AUTOSAR XML (schema 4-0-3)
standard types defined: Boolean, UInt16, UInt8
package /AUTOSAR_Platform/DataConstrs
  range DC_Boolean: raw 0..1
  range DC_UInt16: raw 0..65535
  range DC_UInt8: raw 0..255
package /PATAC/MSM/ComponentTypes
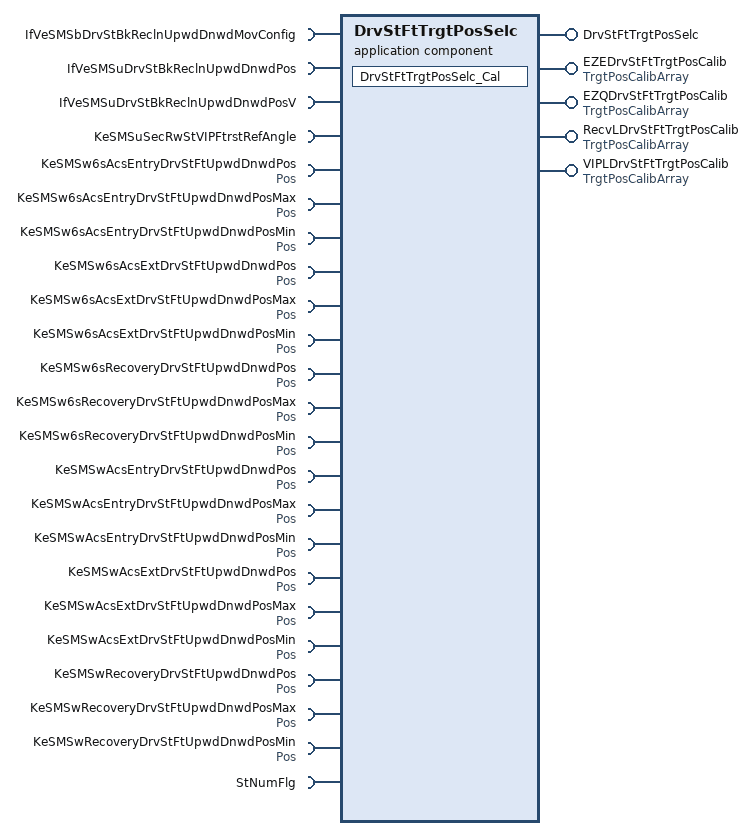
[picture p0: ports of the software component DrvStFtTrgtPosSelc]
  application sw component type DrvStFtTrgtPosSelc
    5 x provide port:
      DrvStFtTrgtPosSelc: server-com-spec{operation=Cal, queue-length=1}, provided-interface=DrvStFtTrgtPosSelc
      EZEDrvStFtTrgtPosCalib: nonqueued-sender-com-spec{data-element=TrgtPosArray, init-value=[4095, 4095, 4095]}, provided-interface=TrgtPosCalibArray
      EZQDrvStFtTrgtPosCalib: nonqueued-sender-com-spec{data-element=TrgtPosArray, init-value=[4095, 4095, 4095]}, provided-interface=TrgtPosCalibArray
      RecvLDrvStFtTrgtPosCalib: nonqueued-sender-com-spec{data-element=TrgtPosArray, init-value=[4095, 4095, 4095]}, provided-interface=TrgtPosCalibArray
      VIPLDrvStFtTrgtPosCalib: nonqueued-sender-com-spec{data-element=TrgtPosArray, init-value=[4095, 4095, 4095]}, provided-interface=TrgtPosCalibArray
    23 x require port:
      IfVeSMSbDrvStBkReclnUpwdDnwdMovConfig: nonqueued-receiver-com-spec{data-element=IfVeSMSbDrvStBkReclnUpwdDnwdMovConfig/Val, filter=data-filter-type=ALWAYS, init-value=0}, required-interface=IfVeSMSbDrvStBkReclnUpwdDnwdMovConfig
      IfVeSMSuDrvStBkReclnUpwdDnwdPos: nonqueued-receiver-com-spec{data-element=IfVeSMSuDrvStBkReclnUpwdDnwdPos/Val, filter=data-filter-type=ALWAYS, init-value=0}, required-interface=IfVeSMSuDrvStBkReclnUpwdDnwdPos
      IfVeSMSuDrvStBkReclnUpwdDnwdPosV: nonqueued-receiver-com-spec{data-element=IfVeSMSuDrvStBkReclnUpwdDnwdPosV/Val, filter=data-filter-type=ALWAYS, init-value=0}, required-interface=IfVeSMSuDrvStBkReclnUpwdDnwdPosV
      KeSMSuSecRwStVIPFtrstRefAngle: parameter-require-com-spec{init-value=110, parameter=KeSMSuSecRwStVIPFtrstRefAngle/Val}, required-interface=KeSMSuSecRwStVIPFtrstRefAngle
      KeSMSw6sAcsEntryDrvStFtUpwdDnwdPos: parameter-require-com-spec{init-value=0, parameter=Pos/Val}, required-interface=Pos
      KeSMSw6sAcsEntryDrvStFtUpwdDnwdPosMax: parameter-require-com-spec{init-value=0, parameter=Pos/Val}, required-interface=Pos
      KeSMSw6sAcsEntryDrvStFtUpwdDnwdPosMin: parameter-require-com-spec{init-value=0, parameter=Pos/Val}, required-interface=Pos
      KeSMSw6sAcsExtDrvStFtUpwdDnwdPos: parameter-require-com-spec{init-value=0, parameter=Pos/Val}, required-interface=Pos
      KeSMSw6sAcsExtDrvStFtUpwdDnwdPosMax: parameter-require-com-spec{init-value=0, parameter=Pos/Val}, required-interface=Pos
      KeSMSw6sAcsExtDrvStFtUpwdDnwdPosMin: parameter-require-com-spec{init-value=0, parameter=Pos/Val}, required-interface=Pos
      KeSMSw6sRecoveryDrvStFtUpwdDnwdPos: parameter-require-com-spec{init-value=0, parameter=Pos/Val}, required-interface=Pos
      KeSMSw6sRecoveryDrvStFtUpwdDnwdPosMax: parameter-require-com-spec{init-value=0, parameter=Pos/Val}, required-interface=Pos
      KeSMSw6sRecoveryDrvStFtUpwdDnwdPosMin: parameter-require-com-spec{init-value=0, parameter=Pos/Val}, required-interface=Pos
      KeSMSwAcsEntryDrvStFtUpwdDnwdPos: parameter-require-com-spec{init-value=0, parameter=Pos/Val}, required-interface=Pos
      KeSMSwAcsEntryDrvStFtUpwdDnwdPosMax: parameter-require-com-spec{init-value=0, parameter=Pos/Val}, required-interface=Pos
      KeSMSwAcsEntryDrvStFtUpwdDnwdPosMin: parameter-require-com-spec{init-value=0, parameter=Pos/Val}, required-interface=Pos
      KeSMSwAcsExtDrvStFtUpwdDnwdPos: parameter-require-com-spec{init-value=0, parameter=Pos/Val}, required-interface=Pos
      KeSMSwAcsExtDrvStFtUpwdDnwdPosMax: parameter-require-com-spec{init-value=0, parameter=Pos/Val}, required-interface=Pos
      KeSMSwAcsExtDrvStFtUpwdDnwdPosMin: parameter-require-com-spec{init-value=0, parameter=Pos/Val}, required-interface=Pos
      KeSMSwRecoveryDrvStFtUpwdDnwdPos: parameter-require-com-spec{init-value=0, parameter=Pos/Val}, required-interface=Pos
      KeSMSwRecoveryDrvStFtUpwdDnwdPosMax: parameter-require-com-spec{init-value=0, parameter=Pos/Val}, required-interface=Pos
      KeSMSwRecoveryDrvStFtUpwdDnwdPosMin: parameter-require-com-spec{init-value=0, parameter=Pos/Val}, required-interface=Pos
      StNumFlg: required-interface=StNumFlg
        required-com-specs:
          data-element=Is4s, filter=data-filter-type=ALWAYS, init-value=0
          data-element=Is6s, filter=data-filter-type=ALWAYS, init-value=0
          data-element=Is6s7s, filter=data-filter-type=ALWAYS, init-value=0
          data-element=Is7s, filter=data-filter-type=ALWAYS, init-value=0
    behavior DrvStFtTrgtPosSelc_InternalBehavior
      operation invoked event OIT_DrvStFtTrgtPosSelc_Cal_DrvStFtTrgtPosSelc_Cal: start-on-event=DrvStFtTrgtPosSelc_Cal, operation=DrvStFtTrgtPosSelc.Cal
      runnable DrvStFtTrgtPosSelc_Cal
        data-receive-point-by-arguments:
          7 x access:
            REC_IfVeSMSbDrvStBkReclnUpwdDnwdMovConfig_Val: accessed-variable=IfVeSMSbDrvStBkReclnUpwdDnwdMovConfig.Val
            REC_IfVeSMSuDrvStBkReclnUpwdDnwdPos_Val: accessed-variable=IfVeSMSuDrvStBkReclnUpwdDnwdPos.Val
            REC_IfVeSMSuDrvStBkReclnUpwdDnwdPosV_Val: accessed-variable=IfVeSMSuDrvStBkReclnUpwdDnwdPosV.Val
            REC_StNumFlg_Is4s: accessed-variable=StNumFlg.Is4s
            REC_StNumFlg_Is6s: accessed-variable=StNumFlg.Is6s
            REC_StNumFlg_Is6s7s: accessed-variable=StNumFlg.Is6s7s
            REC_StNumFlg_Is7s: accessed-variable=StNumFlg.Is7s
        data-send-points:
          4 x access:
            SEND_EZEDrvStFtTrgtPosCalib_TrgtPosArray: accessed-variable=EZEDrvStFtTrgtPosCalib.TrgtPosArray
            SEND_EZQDrvStFtTrgtPosCalib_TrgtPosArray: accessed-variable=EZQDrvStFtTrgtPosCalib.TrgtPosArray
            SEND_RecvLDrvStFtTrgtPosCalib_TrgtPosArray: accessed-variable=RecvLDrvStFtTrgtPosCalib.TrgtPosArray
            SEND_VIPLDrvStFtTrgtPosCalib_TrgtPosArray: accessed-variable=VIPLDrvStFtTrgtPosCalib.TrgtPosArray
        19 x parameter access:
          PA_KeSMSuSecRwStVIPFtrstRefAngle_Val: accessed-parameter=KeSMSuSecRwStVIPFtrstRefAngle.Val
          PA_KeSMSw6sAcsEntryDrvStFtUpwdDnwdPos_Val: accessed-parameter=KeSMSw6sAcsEntryDrvStFtUpwdDnwdPos.Val
          PA_KeSMSw6sAcsEntryDrvStFtUpwdDnwdPosMax_Val: accessed-parameter=KeSMSw6sAcsEntryDrvStFtUpwdDnwdPosMax.Val
          PA_KeSMSw6sAcsEntryDrvStFtUpwdDnwdPosMin_Val: accessed-parameter=KeSMSw6sAcsEntryDrvStFtUpwdDnwdPosMin.Val
          PA_KeSMSw6sAcsExtDrvStFtUpwdDnwdPos_Val: accessed-parameter=KeSMSw6sAcsExtDrvStFtUpwdDnwdPos.Val
          PA_KeSMSw6sAcsExtDrvStFtUpwdDnwdPosMax_Val: accessed-parameter=KeSMSw6sAcsExtDrvStFtUpwdDnwdPosMax.Val
          PA_KeSMSw6sAcsExtDrvStFtUpwdDnwdPosMin_Val: accessed-parameter=KeSMSw6sAcsExtDrvStFtUpwdDnwdPosMin.Val
          PA_KeSMSw6sRecoveryDrvStFtUpwdDnwdPos_Val: accessed-parameter=KeSMSw6sRecoveryDrvStFtUpwdDnwdPos.Val
          PA_KeSMSw6sRecoveryDrvStFtUpwdDnwdPosMax_Val: accessed-parameter=KeSMSw6sRecoveryDrvStFtUpwdDnwdPosMax.Val
          PA_KeSMSw6sRecoveryDrvStFtUpwdDnwdPosMin_Val: accessed-parameter=KeSMSw6sRecoveryDrvStFtUpwdDnwdPosMin.Val
          PA_KeSMSwAcsEntryDrvStFtUpwdDnwdPos_Val: accessed-parameter=KeSMSwAcsEntryDrvStFtUpwdDnwdPos.Val
          PA_KeSMSwAcsEntryDrvStFtUpwdDnwdPosMax_Val: accessed-parameter=KeSMSwAcsEntryDrvStFtUpwdDnwdPosMax.Val
          PA_KeSMSwAcsEntryDrvStFtUpwdDnwdPosMin_Val: accessed-parameter=KeSMSwAcsEntryDrvStFtUpwdDnwdPosMin.Val
          PA_KeSMSwAcsExtDrvStFtUpwdDnwdPos_Val: accessed-parameter=KeSMSwAcsExtDrvStFtUpwdDnwdPos.Val
          PA_KeSMSwAcsExtDrvStFtUpwdDnwdPosMax_Val: accessed-parameter=KeSMSwAcsExtDrvStFtUpwdDnwdPosMax.Val
          PA_KeSMSwAcsExtDrvStFtUpwdDnwdPosMin_Val: accessed-parameter=KeSMSwAcsExtDrvStFtUpwdDnwdPosMin.Val
          PA_KeSMSwRecoveryDrvStFtUpwdDnwdPos_Val: accessed-parameter=KeSMSwRecoveryDrvStFtUpwdDnwdPos.Val
          PA_KeSMSwRecoveryDrvStFtUpwdDnwdPosMax_Val: accessed-parameter=KeSMSwRecoveryDrvStFtUpwdDnwdPosMax.Val
          PA_KeSMSwRecoveryDrvStFtUpwdDnwdPosMin_Val: accessed-parameter=KeSMSwRecoveryDrvStFtUpwdDnwdPosMin.Val
  swc implementation DrvStFtTrgtPosSelc_Implementation: behavior=DrvStFtTrgtPosSelc_InternalBehavior
    code-descriptors:
      code Default: artifact-descriptors=autosar-engineering-object={short-label=Default, category=SWSRC}
package /PATAC/MSM/ModeAdjust/CalPortInterface
  parameter interface Pos
    parameter data prototype Val: sw-calibration-access=READ-WRITE, type=UInt16
package /PATAC/MSM/ModeAdjust/DataType
  impl type TrgtPosCalibArray: category=ARRAY, sw-calibration-access=READ-ONLY, type-emitter=RTE  # 0:pos 1:max 2:min
    element Element: array-size=3, array-size-semantics=FIXED-SIZE, implementation-data-type=UInt16, invalid-value=0
package /PATAC/MSM/ModeAdjust/Interfaces
  sender receiver interface IfVeSMSuDrvStBkReclnUpwdDnwdPosV: invalidation-policy{data-element=IfVeSMSuDrvStBkReclnUpwdDnwdPosV/Val, handle-invalid=DONT-INVALIDATE}
    data Val: type=Boolean
package /PATAC/MSM/ModeAdjust/PortInterface
  client server interface DrvStFtTrgtPosSelc
    operation Cal
  sender receiver interface StNumFlg
    4 x data, all with type=Boolean:
      Is4s
      Is6s
      Is6s7s
      Is7s
    invalidation-policys:
      data-element=Is7s, handle-invalid=DONT-INVALIDATE
      data-element=Is6s, handle-invalid=DONT-INVALIDATE
      data-element=Is4s, handle-invalid=DONT-INVALIDATE
      data-element=Is6s7s, handle-invalid=DONT-INVALIDATE
  sender receiver interface TrgtPosCalibArray: invalidation-policy{data-element=TrgtPosArray, handle-invalid=DONT-INVALIDATE}
    data TrgtPosArray: type=TrgtPosCalibArray  # 0:Pos 1:Max 2:Min
package /PATAC/MSM/PortInterfaces
  parameter interface KeSMSuSecRwStVIPFtrstRefAngle
    parameter data prototype Val: sw-calibration-access=READ-WRITE, type=UInt8
  sender receiver interface IfVeSMSbDrvStBkReclnUpwdDnwdMovConfig: invalidation-policy{data-element=IfVeSMSbDrvStBkReclnUpwdDnwdMovConfig/Val, handle-invalid=DONT-INVALIDATE}
    data Val: type=Boolean
  sender receiver interface IfVeSMSuDrvStBkReclnUpwdDnwdPos: invalidation-policy{data-element=IfVeSMSuDrvStBkReclnUpwdDnwdPos/Val, handle-invalid=DONT-INVALIDATE}
    data Val: type=UInt16
